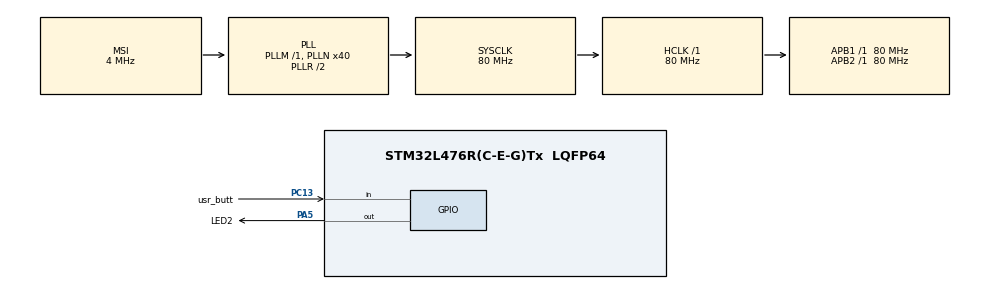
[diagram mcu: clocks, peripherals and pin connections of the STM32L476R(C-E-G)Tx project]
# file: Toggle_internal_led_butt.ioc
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Mcu.Family=STM32L4
Mcu.Name=STM32L476R(C-E-G)Tx
Mcu.Package=LQFP64
NVIC.PriorityGroup=NVIC_PRIORITYGROUP_4
PA5.GPIO_Label=LED2
PA5.Signal=GPIO_Output
PC13.GPIO_Label=usr_butt
PC13.GPIO_PuPd=GPIO_PULLUP
PC13.Signal=GPIO_Input
PH0-OSC_IN\ (PH0).Mode=HSE-External-Oscillator
PH0-OSC_IN\ (PH0).Signal=RCC_OSC_IN
PH1-OSC_OUT\ (PH1).Mode=HSE-External-Oscillator
PH1-OSC_OUT\ (PH1).Signal=RCC_OSC_OUT
ProjectManager.HeapSize=0x200
ProjectManager.StackSize=0x400
ProjectManager.TargetToolchain=STM32CubeIDE
RCC.AHBFreq_Value=80000000
RCC.APB1Freq_Value=80000000
RCC.APB1TimFreq_Value=80000000
RCC.APB2Freq_Value=80000000
RCC.APB2TimFreq_Value=80000000
RCC.CortexFreq_Value=80000000
RCC.HCLKFreq_Value=80000000
RCC.HSE_VALUE=8000000
RCC.HSI_VALUE=16000000
RCC.LSE_VALUE=32768
RCC.MSI_VALUE=4000000
RCC.PLLN=40
RCC.SYSCLKFreq_VALUE=80000000
RCC.SYSCLKSource=RCC_SYSCLKSOURCE_PLLCLK
RCC.VCOOutputFreq_Value=160000000
board=custom

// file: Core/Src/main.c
/* USER CODE BEGIN Header */
/**
  ******************************************************************************
  * @file           : main.c
  * @brief          : Main program body
  ******************************************************************************
  * @attention
  *
  * Copyright (c) 2025 STMicroelectronics.
  * All rights reserved.
  *
  * This software is licensed under terms that can be found in the LICENSE file
  * in the root directory of this software component.
  * If no LICENSE file comes with this software, it is provided AS-IS.
  *
  ******************************************************************************
  */
/* USER CODE END Header */
#include "main.h"

/* USER CODE BEGIN PV */
uint8_t buttonState = 0;      // Current button state
uint8_t lastButtonState = 0;  // Last button state to detect change

/* USER CODE END PV */

void SystemClock_Config(void);
static void MX_GPIO_Init(void);

int main(void)
{

  /* MCU Configuration--------------------------------------------------------*/

  /* Reset of all peripherals, Initializes the Flash interface and the Systick. */
  HAL_Init();

  /* Configure the system clock */
  SystemClock_Config();

  /* Initialize all configured peripherals */
  MX_GPIO_Init();

  /* Infinite loop */
  while (1)
  {
	  // Read the current state of the button (PC13)
	      buttonState = HAL_GPIO_ReadPin(GPIOC, GPIO_PIN_13);

	      // Check for button press (transition from 1 to 0, since active-low)
	      if (buttonState == 0 && lastButtonState == 1)
	      {
	        HAL_GPIO_TogglePin(GPIOA, GPIO_PIN_5); // Toggle LED on PA5
	        HAL_Delay(50); // Simple debounce delay (50 ms)
	      }

	      // Update last button state
	      lastButtonState = buttonState;

  }
}

void SystemClock_Config(void)
{
  RCC_OscInitTypeDef RCC_OscInitStruct = {0};
  RCC_ClkInitTypeDef RCC_ClkInitStruct = {0};

  /** Configure the main internal regulator output voltage
  */
  if (HAL_PWREx_ControlVoltageScaling(PWR_REGULATOR_VOLTAGE_SCALE1) != HAL_OK)
  {
    Error_Handler();
  }

  /** Initializes the RCC Oscillators according to the specified parameters
  * in the RCC_OscInitTypeDef structure.
  */
  RCC_OscInitStruct.OscillatorType = RCC_OSCILLATORTYPE_MSI;
  RCC_OscInitStruct.MSIState = RCC_MSI_ON;
  RCC_OscInitStruct.MSICalibrationValue = 0;
  RCC_OscInitStruct.MSIClockRange = RCC_MSIRANGE_6;
  RCC_OscInitStruct.PLL.PLLState = RCC_PLL_ON;
  RCC_OscInitStruct.PLL.PLLSource = RCC_PLLSOURCE_MSI;
  RCC_OscInitStruct.PLL.PLLM = 1;
  RCC_OscInitStruct.PLL.PLLN = 40;
  RCC_OscInitStruct.PLL.PLLP = RCC_PLLP_DIV7;
  RCC_OscInitStruct.PLL.PLLQ = RCC_PLLQ_DIV2;
  RCC_OscInitStruct.PLL.PLLR = RCC_PLLR_DIV2;
  if (HAL_RCC_OscConfig(&RCC_OscInitStruct) != HAL_OK)
  {
    Error_Handler();
  }

  /** Initializes the CPU, AHB and APB buses clocks
  */
  RCC_ClkInitStruct.ClockType = RCC_CLOCKTYPE_HCLK|RCC_CLOCKTYPE_SYSCLK
                              |RCC_CLOCKTYPE_PCLK1|RCC_CLOCKTYPE_PCLK2;
  RCC_ClkInitStruct.SYSCLKSource = RCC_SYSCLKSOURCE_PLLCLK;
  RCC_ClkInitStruct.AHBCLKDivider = RCC_SYSCLK_DIV1;
  RCC_ClkInitStruct.APB1CLKDivider = RCC_HCLK_DIV1;
  RCC_ClkInitStruct.APB2CLKDivider = RCC_HCLK_DIV1;

  if (HAL_RCC_ClockConfig(&RCC_ClkInitStruct, FLASH_LATENCY_4) != HAL_OK)
  {
    Error_Handler();
  }
}

static void MX_GPIO_Init(void)
{
  GPIO_InitTypeDef GPIO_InitStruct = {0};

  /* GPIO Ports Clock Enable */
  __HAL_RCC_GPIOC_CLK_ENABLE();
  __HAL_RCC_GPIOH_CLK_ENABLE();
  __HAL_RCC_GPIOA_CLK_ENABLE();

  /*Configure GPIO pin Output Level */
  HAL_GPIO_WritePin(LED2_GPIO_Port, LED2_Pin, GPIO_PIN_RESET);

  /*Configure GPIO pin : usr_butt_Pin */
  GPIO_InitStruct.Pin = usr_butt_Pin;
  GPIO_InitStruct.Mode = GPIO_MODE_INPUT;
  GPIO_InitStruct.Pull = GPIO_PULLUP;
  HAL_GPIO_Init(usr_butt_GPIO_Port, &GPIO_InitStruct);

  /*Configure GPIO pin : LED2_Pin */
  GPIO_InitStruct.Pin = LED2_Pin;
  GPIO_InitStruct.Mode = GPIO_MODE_OUTPUT_PP;
  GPIO_InitStruct.Pull = GPIO_NOPULL;
  GPIO_InitStruct.Speed = GPIO_SPEED_FREQ_LOW;
  HAL_GPIO_Init(LED2_GPIO_Port, &GPIO_InitStruct);

}

void Error_Handler(void)
{
  __disable_irq();
  while (1)
  {
  }
}
